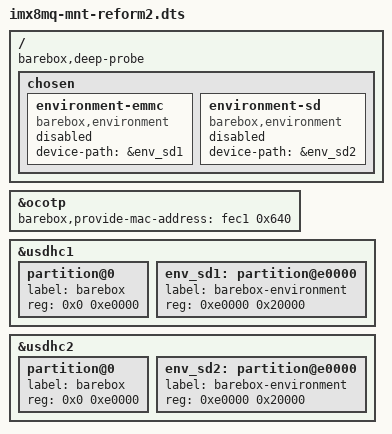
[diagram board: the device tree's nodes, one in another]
// SPDX-License-Identifier: (GPL-2.0 OR MIT)
/*
 * Copyright 2019-2020 MNT Research GmbH
 * Copyright 2020 Lucas Stach <dev@lynxeye.de>
 */

/dts-v1/;

#include <arm64/freescale/imx8mq-mnt-reform2.dts>
#include "imx8mq.dtsi"
#include "imx8mq-ddrc.dtsi"

/ {
	barebox,deep-probe;

	chosen {
		environment-emmc {
			compatible = "barebox,environment";
			device-path = &env_sd1;
			status = "disabled";
		};

		environment-sd {
			compatible = "barebox,environment";
			device-path = &env_sd2;
			status = "disabled";
		};
	};
};

&ocotp {
	barebox,provide-mac-address = <&fec1 0x640>;
};

&usdhc1 {
	#address-cells = <1>;
	#size-cells = <1>;

	partition@0 {
		label = "barebox";
		reg = <0x0 0xe0000>;
	};

	env_sd1: partition@e0000 {
		label = "barebox-environment";
		reg = <0xe0000 0x20000>;
	};
};

&usdhc2 {
	#address-cells = <1>;
	#size-cells = <1>;

	partition@0 {
		label = "barebox";
		reg = <0x0 0xe0000>;
	};

	env_sd2: partition@e0000 {
		label = "barebox-environment";
		reg = <0xe0000 0x20000>;
	};
};
